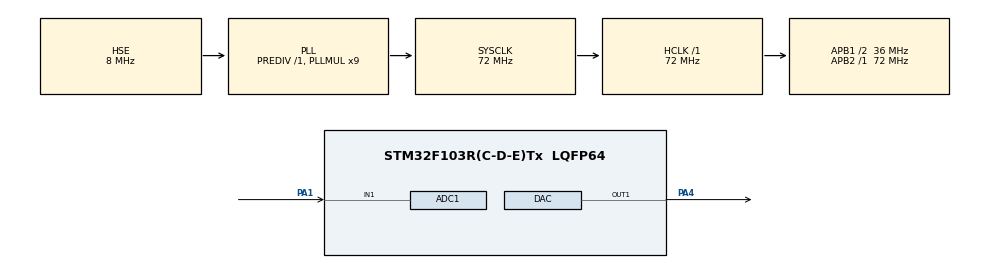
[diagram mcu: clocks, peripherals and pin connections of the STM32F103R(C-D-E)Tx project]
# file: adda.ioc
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ADC1.Channel-0\#ChannelRegularConversion=ADC_CHANNEL_1
ADC1.ContinuousConvMode=ENABLE
ADC1.ExternalTrigConv=ADC_EXTERNALTRIGCONV_T3_TRGO
ADC1.NbrOfConversionFlag=1
ADC1.Rank-0\#ChannelRegularConversion=1
ADC1.SamplingTime-0\#ChannelRegularConversion=ADC_SAMPLETIME_1CYCLE_5
ADC1.master=1
DAC.DAC_OutputBuffer=DAC_OUTPUTBUFFER_DISABLE
DAC.DAC_Trigger=DAC_TRIGGER_T2_TRGO
Dma.ADC1.0.Direction=DMA_PERIPH_TO_MEMORY
Dma.ADC1.0.Instance=DMA1_Channel1
Dma.ADC1.0.MemDataAlignment=DMA_MDATAALIGN_WORD
Dma.ADC1.0.MemInc=DMA_MINC_ENABLE
Dma.ADC1.0.Mode=DMA_NORMAL
Dma.ADC1.0.PeriphDataAlignment=DMA_PDATAALIGN_WORD
Dma.ADC1.0.PeriphInc=DMA_PINC_DISABLE
Dma.ADC1.0.Priority=DMA_PRIORITY_HIGH
Dma.DAC_CH1.1.Direction=DMA_MEMORY_TO_PERIPH
Dma.DAC_CH1.1.Instance=DMA2_Channel3
Dma.DAC_CH1.1.MemDataAlignment=DMA_MDATAALIGN_WORD
Dma.DAC_CH1.1.MemInc=DMA_MINC_ENABLE
Dma.DAC_CH1.1.Mode=DMA_NORMAL
Dma.DAC_CH1.1.PeriphDataAlignment=DMA_PDATAALIGN_WORD
Dma.DAC_CH1.1.PeriphInc=DMA_PINC_DISABLE
Dma.DAC_CH1.1.Priority=DMA_PRIORITY_LOW
Dma.Request0=ADC1
Dma.Request1=DAC_CH1
Mcu.Family=STM32F1
Mcu.Name=STM32F103R(C-D-E)Tx
Mcu.Package=LQFP64
NVIC.ADC1_2_IRQn=true\:0\:0\:false\:false\:true\:true\:true
NVIC.DMA1_Channel1_IRQn=true\:0\:0\:false\:false\:true\:false\:true
NVIC.DMA2_Channel3_IRQn=true\:0\:0\:false\:false\:true\:false\:true
NVIC.PriorityGroup=NVIC_PRIORITYGROUP_4
PA1.Signal=ADCx_IN1
PA13.Mode=Serial_Wire
PA13.Signal=SYS_JTMS-SWDIO
PA14.Mode=Serial_Wire
PA14.Signal=SYS_JTCK-SWCLK
PA4.Signal=COMP_DAC1_group
PC14-OSC32_IN.Mode=LSE-External-Oscillator
PC14-OSC32_IN.Signal=RCC_OSC32_IN
PC15-OSC32_OUT.Mode=LSE-External-Oscillator
PC15-OSC32_OUT.Signal=RCC_OSC32_OUT
PD0-OSC_IN.Mode=HSE-External-Oscillator
PD0-OSC_IN.Signal=RCC_OSC_IN
PD1-OSC_OUT.Mode=HSE-External-Oscillator
PD1-OSC_OUT.Signal=RCC_OSC_OUT
ProjectManager.HeapSize=0x200
ProjectManager.StackSize=0x400
ProjectManager.TargetToolchain=MDK-ARM V5.32
RCC.ADCPresc=RCC_ADCPCLK2_DIV6
RCC.AHBFreq_Value=72000000
RCC.APB1CLKDivider=RCC_HCLK_DIV2
RCC.APB1Freq_Value=36000000
RCC.APB1TimFreq_Value=72000000
RCC.APB2Freq_Value=72000000
RCC.APB2TimFreq_Value=72000000
RCC.HCLKFreq_Value=72000000
RCC.PLLMUL=RCC_PLL_MUL9
RCC.PLLSourceVirtual=RCC_PLLSOURCE_HSE
RCC.SYSCLKFreq_VALUE=72000000
RCC.SYSCLKSource=RCC_SYSCLKSOURCE_PLLCLK
RCC.USBFreq_Value=72000000
SH.ADCx_IN1.0=ADC1_IN1,IN1
SH.COMP_DAC1_group.0=DAC_OUT1,DAC_OUT1
TIM2.AutoReloadPreload=TIM_AUTORELOAD_PRELOAD_ENABLE
TIM2.Period=2-1
TIM2.TIM_MasterOutputTrigger=TIM_TRGO_UPDATE
TIM3.AutoReloadPreload=TIM_AUTORELOAD_PRELOAD_ENABLE
TIM3.Period=2-1
TIM3.TIM_MasterOutputTrigger=TIM_TRGO_UPDATE
VP_TIM2_VS_ClockSourceINT.Mode=Internal
VP_TIM3_VS_ClockSourceINT.Mode=Internal
board=custom

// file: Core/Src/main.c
/* USER CODE BEGIN Header */
/**
  ******************************************************************************
  * @file           : main.c
  * @brief          : Main program body
  ******************************************************************************
  * @attention
  *
  * Copyright (c) 2022 STMicroelectronics.
  * All rights reserved.
  *
  * This software is licensed under terms that can be found in the LICENSE file
  * in the root directory of this software component.
  * If no LICENSE file comes with this software, it is provided AS-IS.
  *
  ******************************************************************************
  */
/* USER CODE END Header */
#include "main.h"
#include "adc.h"
#include "dac.h"
#include "dma.h"
#include "tim.h"
#include "gpio.h"

void SystemClock_Config(void);

/* USER CODE BEGIN 0 */
uint32_t AD_Value[100]={0};
int i0=0;
int i1=0;
int flag0=0,flag1=0;
int i=0;
/* USER CODE END 0 */

int main(void)
{

  /* MCU Configuration--------------------------------------------------------*/

  /* Reset of all peripherals, Initializes the Flash interface and the Systick. */
  HAL_Init();

  /* Configure the system clock */
  SystemClock_Config();

  /* Initialize all configured peripherals */
  MX_GPIO_Init();
  MX_DMA_Init();
  MX_ADC1_Init();
  MX_DAC_Init();
  MX_TIM2_Init();
  MX_TIM3_Init();
  /* USER CODE BEGIN 2 */

	HAL_TIM_Base_Start(&htim3);
	HAL_TIM_Base_Start(&htim2);

	HAL_ADC_Start_DMA(&hadc1,(uint32_t *)AD_Value,100);
  /* USER CODE END 2 */

  /* Infinite loop */
  while (1)
  {

  }
}

void SystemClock_Config(void)
{
  RCC_OscInitTypeDef RCC_OscInitStruct = {0};
  RCC_ClkInitTypeDef RCC_ClkInitStruct = {0};
  RCC_PeriphCLKInitTypeDef PeriphClkInit = {0};

  /** Initializes the RCC Oscillators according to the specified parameters
  * in the RCC_OscInitTypeDef structure.
  */
  RCC_OscInitStruct.OscillatorType = RCC_OSCILLATORTYPE_HSE;
  RCC_OscInitStruct.HSEState = RCC_HSE_ON;
  RCC_OscInitStruct.HSEPredivValue = RCC_HSE_PREDIV_DIV1;
  RCC_OscInitStruct.HSIState = RCC_HSI_ON;
  RCC_OscInitStruct.PLL.PLLState = RCC_PLL_ON;
  RCC_OscInitStruct.PLL.PLLSource = RCC_PLLSOURCE_HSE;
  RCC_OscInitStruct.PLL.PLLMUL = RCC_PLL_MUL9;
  if (HAL_RCC_OscConfig(&RCC_OscInitStruct) != HAL_OK)
  {
    Error_Handler();
  }
  /** Initializes the CPU, AHB and APB buses clocks
  */
  RCC_ClkInitStruct.ClockType = RCC_CLOCKTYPE_HCLK|RCC_CLOCKTYPE_SYSCLK
                              |RCC_CLOCKTYPE_PCLK1|RCC_CLOCKTYPE_PCLK2;
  RCC_ClkInitStruct.SYSCLKSource = RCC_SYSCLKSOURCE_PLLCLK;
  RCC_ClkInitStruct.AHBCLKDivider = RCC_SYSCLK_DIV1;
  RCC_ClkInitStruct.APB1CLKDivider = RCC_HCLK_DIV2;
  RCC_ClkInitStruct.APB2CLKDivider = RCC_HCLK_DIV1;

  if (HAL_RCC_ClockConfig(&RCC_ClkInitStruct, FLASH_LATENCY_2) != HAL_OK)
  {
    Error_Handler();
  }
  PeriphClkInit.PeriphClockSelection = RCC_PERIPHCLK_ADC;
  PeriphClkInit.AdcClockSelection = RCC_ADCPCLK2_DIV6;
  if (HAL_RCCEx_PeriphCLKConfig(&PeriphClkInit) != HAL_OK)
  {
    Error_Handler();
  }
}

/* USER CODE BEGIN 4 */

void HAL_ADC_ConvCpltCallback(ADC_HandleTypeDef* hadc)
{
	flag0++;

		i0=1;
//		if(i0==1&&i1==1){
//			i0=0;
//			i1=0;
//	}
		while(!i1){

		}
		if(flag0%2==0){
			HAL_DAC_Start_DMA(&hdac,DAC_CHANNEL_1,(uint32_t *)AD_Value,50,DAC_ALIGN_12B_R);
			}
		else {
			HAL_DAC_Start_DMA(&hdac,DAC_CHANNEL_1,(uint32_t *)&AD_Value[50],50,DAC_ALIGN_12B_R);
		}

		if(flag0==65530){
		flag0=0;
		}

}
void HAL_DAC_ConvCpltCallbackCh1(DAC_HandleTypeDef* hdac){
	flag1++;
	i1=1;
	while(!i0){

	}
	if(flag1%2==0){
		HAL_ADC_Start_DMA(&hadc1,(uint32_t *)AD_Value,50);
	}
	else {
		HAL_ADC_Start_DMA(&hadc1,(uint32_t *)&AD_Value[50],50);

	}
	if(flag1==65530){
		flag1=0;
	}
}

void HAL_ADC_ConvHalfCpltCallback(ADC_HandleTypeDef* hadc){
	if(i==0){
		i=1;
		i0=1;
		HAL_DAC_Start_DMA(&hdac,DAC_CHANNEL_1,(uint32_t *)AD_Value,50,DAC_ALIGN_12B_R);
	}

}

/* USER CODE END 4 */

void Error_Handler(void)
{
  __disable_irq();
  while (1)
  {
  }
}
